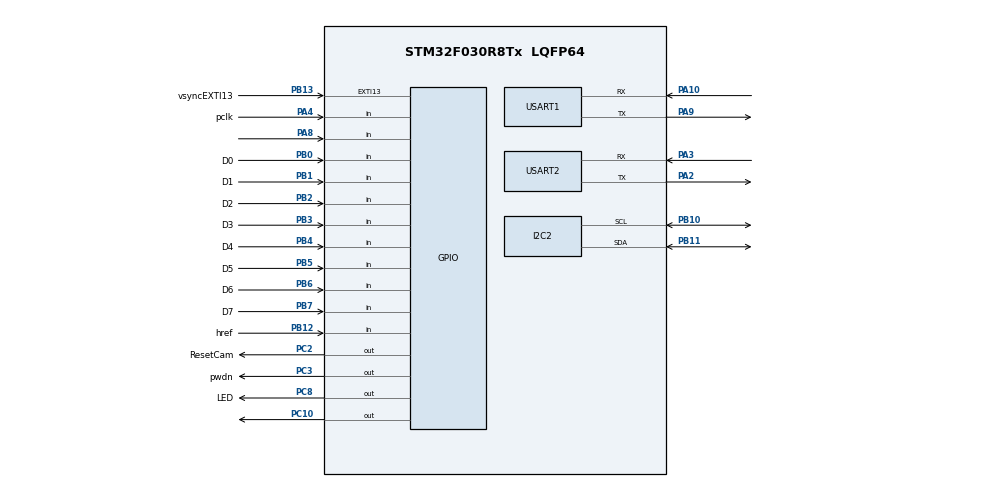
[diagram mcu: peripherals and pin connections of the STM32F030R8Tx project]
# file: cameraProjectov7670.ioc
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Mcu.Family=STM32F0
Mcu.Name=STM32F030R8Tx
Mcu.Package=LQFP64
NVIC.EXTI4_15_IRQn=true\:0\:0\:false\:false\:true\:true\:true\:true
PA10.Mode=Asynchronous
PA10.Signal=USART1_RX
PA2.Mode=Asynchronous
PA2.Signal=USART2_TX
PA3.Mode=Asynchronous
PA3.Signal=USART2_RX
PA4.GPIO_Label=pclk
PA4.Signal=GPIO_Input
PA8.Signal=GPIO_Input
PA9.Mode=Asynchronous
PA9.Signal=USART1_TX
PB0.GPIO_Label=D0
PB0.Signal=GPIO_Input
PB1.GPIO_Label=D1
PB1.Signal=GPIO_Input
PB10.Mode=I2C
PB10.Signal=I2C2_SCL
PB11.Mode=I2C
PB11.Signal=I2C2_SDA
PB12.GPIO_Label=href
PB12.Signal=GPIO_Input
PB13.GPIO_Label=vsyncEXTI13
PB13.Signal=GPXTI13
PB2.GPIO_Label=D2
PB2.Signal=GPIO_Input
PB3.GPIO_Label=D3
PB3.Signal=GPIO_Input
PB4.GPIO_Label=D4
PB4.Signal=GPIO_Input
PB5.GPIO_Label=D5
PB5.Signal=GPIO_Input
PB6.GPIO_Label=D6
PB6.Signal=GPIO_Input
PB7.GPIO_Label=D7
PB7.Signal=GPIO_Input
PC10.Signal=GPIO_Output
PC14-OSC32_IN.Mode=LSE-External-Oscillator
PC14-OSC32_IN.Signal=RCC_OSC32_IN
PC15-OSC32_OUT.Mode=LSE-External-Oscillator
PC15-OSC32_OUT.Signal=RCC_OSC32_OUT
PC2.GPIO_Label=ResetCam
PC2.Signal=GPIO_Output
PC3.GPIO_Label=pwdn
PC3.Signal=GPIO_Output
PC8.GPIO_Label=LED
PC8.Signal=GPIO_Output
PF0-OSC_IN.Mode=HSE-External-Oscillator
PF0-OSC_IN.Signal=RCC_OSC_IN
PF1-OSC_OUT.Mode=HSE-External-Oscillator
PF1-OSC_OUT.Signal=RCC_OSC_OUT
ProjectManager.HeapSize=0x200
ProjectManager.StackSize=0x400
ProjectManager.TargetToolchain=STM32CubeIDE
TIM14.Prescaler=47
TIM3.Channel-PWM\ Generation2\ No\ Output=TIM_CHANNEL_2
TIM3.Period=1
TIM3.Prescaler=1
TIM6.Prescaler=47
USART1.VirtualMode-Asynchronous=VM_ASYNC
USART2.VirtualMode-Asynchronous=VM_ASYNC
VP_CRC_VS_CRC.Mode=CRC_Activate
VP_TIM14_VS_ClockSourceINT.Mode=Enable_Timer
VP_TIM1_VS_ClockSourceINT.Mode=Internal
VP_TIM3_VS_ClockSourceINT.Mode=Internal
VP_TIM3_VS_no_output2.Mode=PWM Generation2 No Output
VP_TIM6_VS_ClockSourceINT.Mode=Enable_Timer
board=custom

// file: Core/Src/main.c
#include "main.h"
#include <ov7670.h>
#include <string.h>
#include <stdio.h>
CRC_HandleTypeDef hcrc;

I2C_HandleTypeDef hi2c2;

TIM_HandleTypeDef htim1;
TIM_HandleTypeDef htim3;
TIM_HandleTypeDef htim6;
TIM_HandleTypeDef htim14;

UART_HandleTypeDef huart1;
UART_HandleTypeDef huart2;

void SystemClock_Config(void);
static void MX_GPIO_Init(void);
static void MX_USART2_UART_Init(void);
static void MX_I2C2_Init(void);
static void MX_TIM6_Init(void);
static void MX_TIM14_Init(void);
static void MX_CRC_Init(void);
static void MX_TIM3_Init(void);
static void MX_USART1_UART_Init(void);
static void MX_TIM1_Init(void);

#define DHT11_PORT GPIOC
#define DHT11_PIN GPIO_PIN_10
uint8_t RHI, RHD, TCI, TCD, SUM;
uint32_t pMillis, cMillis;
float tCelsius = 0;
float tFahrenheit = 0;
float RH = 0;

void microDelay (uint16_t delay)
{
  __HAL_TIM_SET_COUNTER(&htim1, 0);
  while (__HAL_TIM_GET_COUNTER(&htim1) < delay);
}
uint8_t DHT11_Start (void)
{
  uint8_t Response = 0;
  GPIO_InitTypeDef GPIO_InitStructPrivate = {0};
  GPIO_InitStructPrivate.Pin = DHT11_PIN;
  GPIO_InitStructPrivate.Mode = GPIO_MODE_OUTPUT_PP;
  GPIO_InitStructPrivate.Speed = GPIO_SPEED_FREQ_LOW;
  GPIO_InitStructPrivate.Pull = GPIO_NOPULL;
  HAL_GPIO_Init(DHT11_PORT, &GPIO_InitStructPrivate); // set the pin as output
  HAL_GPIO_WritePin (DHT11_PORT, DHT11_PIN, 0);   // pull the pin low
  HAL_Delay(20);   // wait for 20ms
  HAL_GPIO_WritePin (DHT11_PORT, DHT11_PIN, 1);   // pull the pin high
  microDelay (30);   // wait for 30us
  GPIO_InitStructPrivate.Mode = GPIO_MODE_INPUT;
  GPIO_InitStructPrivate.Pull = GPIO_PULLUP;
  HAL_GPIO_Init(DHT11_PORT, &GPIO_InitStructPrivate); // set the pin as input
  microDelay (40);
  if (!(HAL_GPIO_ReadPin (DHT11_PORT, DHT11_PIN)))
  {
    microDelay (80);

    if ((HAL_GPIO_ReadPin (DHT11_PORT, DHT11_PIN))) Response = 1;
  }
  pMillis = HAL_GetTick();
  cMillis = HAL_GetTick();
  while ((HAL_GPIO_ReadPin (DHT11_PORT, DHT11_PIN)) && pMillis + 2 > cMillis)
  {
    cMillis = HAL_GetTick();
  }
  return Response;
}

int main(void)
{
  HAL_Init();
  SystemClock_Config();
  MX_GPIO_Init();
  MX_USART2_UART_Init();
  MX_I2C2_Init();
  MX_TIM6_Init();
  MX_TIM14_Init();
  MX_CRC_Init();
  MX_TIM3_Init();
  MX_USART1_UART_Init();
  MX_TIM1_Init();
  /* USER CODE BEGIN 2 */
      HAL_TIM_Base_Start(&htim1);

      HAL_TIM_PWM_Start(&htim3, TIM_CHANNEL_2);
          HAL_TIM_Base_Start(&htim6);
          HAL_TIM_Base_Start(&htim14);

          //We wrote 1 the compare counting for being %50 rate of the (Duty Cycle Duty Cycle oranını %50 olmasi icin compare sayimini 1 olarak yazdik).
            //Counter Period Index is 1 that means this value divides the clock signal by 2( Counter Period indexi 1 yani Clock sinyalini 2 ye bölüyor.)
            //Pwm clock value is = 48 / 2 = 24 MHz (Su anki clock degeri = 48 / 2 = 24MHz osiloskopsuz degeri(para yok olcemedik))
            __HAL_TIM_SetCompare(&htim3,TIM_CHANNEL_2,1);
            // Allumer la LED
              HAL_GPIO_WritePin(LED_GPIO_Port, LED_Pin, GPIO_PIN_SET);

            //OV Camera Settings
            ConfigurePWDNandRESETpins();
            //Make little delay for healthy process
            HAL_Delay(1);
            //Reset all registers
                  ov7670_init();
                  //Make little delay for healthy process
                  HAL_Delay(1);

  /* USER CODE END 2 */

  /* Infinite loop */
  /* USER CODE BEGIN WHILE */
  while (1)
  {

	  GetFramesFromOvCam();

  }
  /* USER CODE END 3 */
}

void SystemClock_Config(void)
{
  RCC_OscInitTypeDef RCC_OscInitStruct = {0};
  RCC_ClkInitTypeDef RCC_ClkInitStruct = {0};
  RCC_PeriphCLKInitTypeDef PeriphClkInit = {0};

  /** Initializes the RCC Oscillators according to the specified parameters
  * in the RCC_OscInitTypeDef structure.
  */
  RCC_OscInitStruct.OscillatorType = RCC_OSCILLATORTYPE_HSI;
  RCC_OscInitStruct.HSIState = RCC_HSI_ON;
  RCC_OscInitStruct.HSICalibrationValue = RCC_HSICALIBRATION_DEFAULT;
  RCC_OscInitStruct.PLL.PLLState = RCC_PLL_NONE;
  if (HAL_RCC_OscConfig(&RCC_OscInitStruct) != HAL_OK)
  {
    Error_Handler();
  }

  /** Initializes the CPU, AHB and APB buses clocks
  */
  RCC_ClkInitStruct.ClockType = RCC_CLOCKTYPE_HCLK|RCC_CLOCKTYPE_SYSCLK
                              |RCC_CLOCKTYPE_PCLK1;
  RCC_ClkInitStruct.SYSCLKSource = RCC_SYSCLKSOURCE_HSI;
  RCC_ClkInitStruct.AHBCLKDivider = RCC_SYSCLK_DIV1;
  RCC_ClkInitStruct.APB1CLKDivider = RCC_HCLK_DIV1;

  if (HAL_RCC_ClockConfig(&RCC_ClkInitStruct, FLASH_LATENCY_0) != HAL_OK)
  {
    Error_Handler();
  }
  PeriphClkInit.PeriphClockSelection = RCC_PERIPHCLK_USART1;
  PeriphClkInit.Usart1ClockSelection = RCC_USART1CLKSOURCE_PCLK1;
  if (HAL_RCCEx_PeriphCLKConfig(&PeriphClkInit) != HAL_OK)
  {
    Error_Handler();
  }
}

static void MX_CRC_Init(void)
{

  hcrc.Instance = CRC;
  hcrc.Init.DefaultInitValueUse = DEFAULT_INIT_VALUE_ENABLE;
  hcrc.Init.InputDataInversionMode = CRC_INPUTDATA_INVERSION_NONE;
  hcrc.Init.OutputDataInversionMode = CRC_OUTPUTDATA_INVERSION_DISABLE;
  hcrc.InputDataFormat = CRC_INPUTDATA_FORMAT_BYTES;
  if (HAL_CRC_Init(&hcrc) != HAL_OK)
  {
    Error_Handler();
  }

}

static void MX_I2C2_Init(void)
{

  hi2c2.Instance = I2C2;
  hi2c2.Init.Timing = 0x2000090E;
  hi2c2.Init.OwnAddress1 = 0;
  hi2c2.Init.AddressingMode = I2C_ADDRESSINGMODE_7BIT;
  hi2c2.Init.DualAddressMode = I2C_DUALADDRESS_DISABLE;
  hi2c2.Init.OwnAddress2 = 0;
  hi2c2.Init.OwnAddress2Masks = I2C_OA2_NOMASK;
  hi2c2.Init.GeneralCallMode = I2C_GENERALCALL_DISABLE;
  hi2c2.Init.NoStretchMode = I2C_NOSTRETCH_DISABLE;
  if (HAL_I2C_Init(&hi2c2) != HAL_OK)
  {
    Error_Handler();
  }

  /** Configure Analogue filter
  */
  if (HAL_I2CEx_ConfigAnalogFilter(&hi2c2, I2C_ANALOGFILTER_ENABLE) != HAL_OK)
  {
    Error_Handler();
  }

  /** Configure Digital filter
  */
  if (HAL_I2CEx_ConfigDigitalFilter(&hi2c2, 0) != HAL_OK)
  {
    Error_Handler();
  }

}

static void MX_TIM1_Init(void)
{

  TIM_ClockConfigTypeDef sClockSourceConfig = {0};
  TIM_MasterConfigTypeDef sMasterConfig = {0};

  htim1.Instance = TIM1;
  htim1.Init.Prescaler = 71;
  htim1.Init.CounterMode = TIM_COUNTERMODE_UP;
  htim1.Init.Period = 65535;
  htim1.Init.ClockDivision = TIM_CLOCKDIVISION_DIV1;
  htim1.Init.RepetitionCounter = 0;
  htim1.Init.AutoReloadPreload = TIM_AUTORELOAD_PRELOAD_DISABLE;
  if (HAL_TIM_Base_Init(&htim1) != HAL_OK)
  {
    Error_Handler();
  }
  sClockSourceConfig.ClockSource = TIM_CLOCKSOURCE_INTERNAL;
  if (HAL_TIM_ConfigClockSource(&htim1, &sClockSourceConfig) != HAL_OK)
  {
    Error_Handler();
  }
  sMasterConfig.MasterOutputTrigger = TIM_TRGO_RESET;
  sMasterConfig.MasterSlaveMode = TIM_MASTERSLAVEMODE_DISABLE;
  if (HAL_TIMEx_MasterConfigSynchronization(&htim1, &sMasterConfig) != HAL_OK)
  {
    Error_Handler();
  }

}

static void MX_TIM3_Init(void)
{

  TIM_ClockConfigTypeDef sClockSourceConfig = {0};
  TIM_MasterConfigTypeDef sMasterConfig = {0};
  TIM_OC_InitTypeDef sConfigOC = {0};

  htim3.Instance = TIM3;
  htim3.Init.Prescaler = 1;
  htim3.Init.CounterMode = TIM_COUNTERMODE_UP;
  htim3.Init.Period = 1;
  htim3.Init.ClockDivision = TIM_CLOCKDIVISION_DIV1;
  htim3.Init.AutoReloadPreload = TIM_AUTORELOAD_PRELOAD_DISABLE;
  if (HAL_TIM_Base_Init(&htim3) != HAL_OK)
  {
    Error_Handler();
  }
  sClockSourceConfig.ClockSource = TIM_CLOCKSOURCE_INTERNAL;
  if (HAL_TIM_ConfigClockSource(&htim3, &sClockSourceConfig) != HAL_OK)
  {
    Error_Handler();
  }
  if (HAL_TIM_PWM_Init(&htim3) != HAL_OK)
  {
    Error_Handler();
  }
  sMasterConfig.MasterOutputTrigger = TIM_TRGO_RESET;
  sMasterConfig.MasterSlaveMode = TIM_MASTERSLAVEMODE_DISABLE;
  if (HAL_TIMEx_MasterConfigSynchronization(&htim3, &sMasterConfig) != HAL_OK)
  {
    Error_Handler();
  }
  sConfigOC.OCMode = TIM_OCMODE_PWM1;
  sConfigOC.Pulse = 0;
  sConfigOC.OCPolarity = TIM_OCPOLARITY_HIGH;
  sConfigOC.OCFastMode = TIM_OCFAST_DISABLE;
  if (HAL_TIM_PWM_ConfigChannel(&htim3, &sConfigOC, TIM_CHANNEL_2) != HAL_OK)
  {
    Error_Handler();
  }

}

static void MX_TIM6_Init(void)
{

  htim6.Instance = TIM6;
  htim6.Init.Prescaler = 47;
  htim6.Init.CounterMode = TIM_COUNTERMODE_UP;
  htim6.Init.Period = 65535;
  htim6.Init.AutoReloadPreload = TIM_AUTORELOAD_PRELOAD_DISABLE;
  if (HAL_TIM_Base_Init(&htim6) != HAL_OK)
  {
    Error_Handler();
  }

}

static void MX_TIM14_Init(void)
{

  htim14.Instance = TIM14;
  htim14.Init.Prescaler = 47;
  htim14.Init.CounterMode = TIM_COUNTERMODE_UP;
  htim14.Init.Period = 65535;
  htim14.Init.ClockDivision = TIM_CLOCKDIVISION_DIV1;
  htim14.Init.AutoReloadPreload = TIM_AUTORELOAD_PRELOAD_DISABLE;
  if (HAL_TIM_Base_Init(&htim14) != HAL_OK)
  {
    Error_Handler();
  }

}

static void MX_USART1_UART_Init(void)
{

  huart1.Instance = USART1;
  huart1.Init.BaudRate = 115200;
  huart1.Init.WordLength = UART_WORDLENGTH_8B;
  huart1.Init.StopBits = UART_STOPBITS_1;
  huart1.Init.Parity = UART_PARITY_NONE;
  huart1.Init.Mode = UART_MODE_TX_RX;
  huart1.Init.HwFlowCtl = UART_HWCONTROL_NONE;
  huart1.Init.OverSampling = UART_OVERSAMPLING_16;
  huart1.Init.OneBitSampling = UART_ONE_BIT_SAMPLE_DISABLE;
  huart1.AdvancedInit.AdvFeatureInit = UART_ADVFEATURE_NO_INIT;
  if (HAL_UART_Init(&huart1) != HAL_OK)
  {
    Error_Handler();
  }

}

static void MX_USART2_UART_Init(void)
{

  huart2.Instance = USART2;
  huart2.Init.BaudRate = 115200;
  huart2.Init.WordLength = UART_WORDLENGTH_8B;
  huart2.Init.StopBits = UART_STOPBITS_1;
  huart2.Init.Parity = UART_PARITY_NONE;
  huart2.Init.Mode = UART_MODE_TX_RX;
  huart2.Init.HwFlowCtl = UART_HWCONTROL_NONE;
  huart2.Init.OverSampling = UART_OVERSAMPLING_16;
  huart2.Init.OneBitSampling = UART_ONE_BIT_SAMPLE_DISABLE;
  huart2.AdvancedInit.AdvFeatureInit = UART_ADVFEATURE_NO_INIT;
  if (HAL_UART_Init(&huart2) != HAL_OK)
  {
    Error_Handler();
  }

}

static void MX_GPIO_Init(void)
{
  GPIO_InitTypeDef GPIO_InitStruct = {0};

  /* GPIO Ports Clock Enable */
  __HAL_RCC_GPIOC_CLK_ENABLE();
  __HAL_RCC_GPIOF_CLK_ENABLE();
  __HAL_RCC_GPIOA_CLK_ENABLE();
  __HAL_RCC_GPIOB_CLK_ENABLE();

  /*Configure GPIO pin Output Level */
  HAL_GPIO_WritePin(GPIOC, ResetCam_Pin|pwdn_Pin|LED_Pin|GPIO_PIN_10, GPIO_PIN_RESET);

  /*Configure GPIO pins : ResetCam_Pin pwdn_Pin LED_Pin PC10 */
  GPIO_InitStruct.Pin = ResetCam_Pin|pwdn_Pin|LED_Pin|GPIO_PIN_10;
  GPIO_InitStruct.Mode = GPIO_MODE_OUTPUT_PP;
  GPIO_InitStruct.Pull = GPIO_NOPULL;
  GPIO_InitStruct.Speed = GPIO_SPEED_FREQ_LOW;
  HAL_GPIO_Init(GPIOC, &GPIO_InitStruct);

  /*Configure GPIO pins : pclk_Pin PA8 */
  GPIO_InitStruct.Pin = pclk_Pin|GPIO_PIN_8;
  GPIO_InitStruct.Mode = GPIO_MODE_INPUT;
  GPIO_InitStruct.Pull = GPIO_NOPULL;
  HAL_GPIO_Init(GPIOA, &GPIO_InitStruct);

  /*Configure GPIO pins : D0_Pin D1_Pin D2_Pin href_Pin
                           D3_Pin D4_Pin D5_Pin D6_Pin
                           D7_Pin */
  GPIO_InitStruct.Pin = D0_Pin|D1_Pin|D2_Pin|href_Pin
                          |D3_Pin|D4_Pin|D5_Pin|D6_Pin
                          |D7_Pin;
  GPIO_InitStruct.Mode = GPIO_MODE_INPUT;
  GPIO_InitStruct.Pull = GPIO_NOPULL;
  HAL_GPIO_Init(GPIOB, &GPIO_InitStruct);

  /*Configure GPIO pin : vsyncEXTI13_Pin */
  GPIO_InitStruct.Pin = vsyncEXTI13_Pin;
  GPIO_InitStruct.Mode = GPIO_MODE_IT_RISING;
  GPIO_InitStruct.Pull = GPIO_NOPULL;
  HAL_GPIO_Init(vsyncEXTI13_GPIO_Port, &GPIO_InitStruct);

  /* EXTI interrupt init*/
  HAL_NVIC_SetPriority(EXTI4_15_IRQn, 0, 0);
  HAL_NVIC_EnableIRQ(EXTI4_15_IRQn);

}

void Error_Handler(void)
{
  __disable_irq();
  while (1)
  {
  }
}
